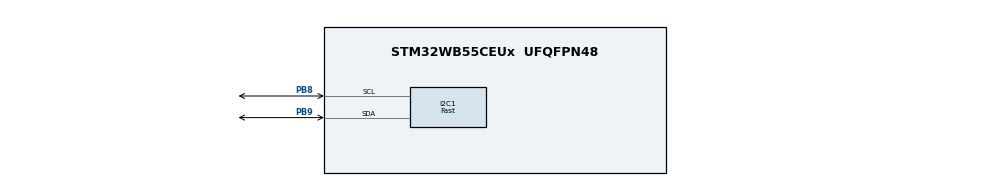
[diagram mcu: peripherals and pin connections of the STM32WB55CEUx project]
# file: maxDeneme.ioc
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I2C1.I2C_Speed_Mode=I2C_Fast
I2C1.Speed=300
I2C1.Timing=0x00000007
Mcu.Family=STM32WB
Mcu.Name=STM32WB55CEUx
Mcu.Package=UFQFPN48
NVIC.PriorityGroup=NVIC_PRIORITYGROUP_4
PB8.Mode=I2C
PB8.Signal=I2C1_SCL
PB9.Mode=I2C
PB9.Signal=I2C1_SDA
ProjectManager.HeapSize=0x200
ProjectManager.StackSize=0x400
ProjectManager.TargetToolchain=STM32CubeIDE
RCC.APB3Freq_Value=16000000
RCC.HSE_VALUE=8000000
RCC.HSI48_VALUE=48000000
RCC.HSI_VALUE=16000000
RCC.LSE_VALUE=32768
RCC.VCOOutputFreq_Value=32000000
board=custom

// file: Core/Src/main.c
/* USER CODE BEGIN Header */
/**
  ******************************************************************************
  * @file           : main.c
  * @brief          : Main program body
  ******************************************************************************
  * @attention
  *
  * Copyright (c) 2023 STMicroelectronics.
  * All rights reserved.
  *
  * This software is licensed under terms that can be found in the LICENSE file
  * in the root directory of this software component.
  * If no LICENSE file comes with this software, it is provided AS-IS.
  *
  ******************************************************************************
  */
/* USER CODE END Header */
#include "main.h"

/* USER CODE BEGIN Includes */
#include "max30102.h"
#include "heartRate.h"
#include "spo2_algorithm.h"
/* USER CODE END Includes */

I2C_HandleTypeDef hi2c1;

void SystemClock_Config(void);
void PeriphCommonClock_Config(void);
static void MX_GPIO_Init(void);
static void MX_I2C1_Init(void);

/* USER CODE BEGIN 0 */
#define MAX_BRIGHTNESS 255

uint32_t irBuffer[100]; //infrared LED sensor data
uint32_t redBuffer[100];  //red LED sensor data

int32_t bufferLength; //data length
int32_t spo2; //SPO2 value
int8_t validSPO2; //indicator to show if the SPO2 calculation is valid
int32_t heartRate; //heart rate value
int8_t validHeartRate; //indicator to show if the heart rate calculation is valid

const uint8_t RATE_SIZE = 4; //Increase this for more averaging. 4 is good.
uint8_t rates[4]; //Array of heart rates
uint8_t rateSpot = 0;
uint32_t lastBeat = 0; //Time at which the last beat occurred

float beatsPerMinute;
int beatAvg;
uint32_t prevTime;
uint8_t flag=0;
uint32_t currentTime;
/* USER CODE END 0 */

int main(void)
{

  /* MCU Configuration--------------------------------------------------------*/

  /* Reset of all peripherals, Initializes the Flash interface and the Systick. */
  HAL_Init();

  /* Configure the system clock */
  SystemClock_Config();

/* Configure the peripherals common clocks */
  PeriphCommonClock_Config();

  /* Initialize all configured peripherals */
  MX_GPIO_Init();
  MX_I2C1_Init();
  /* USER CODE BEGIN 2 */
  SysTick_Config(SystemCoreClock/1000);
  I2C1_init(&hi2c1);
  MAX30102_init();
  //setup(60, 4, 2, 100, 411, 4096);
  //MAX30102_setPulseAmplitudeRed(0x0A);
  /* USER CODE END 2 */

  /* Infinite loop */
  while (1)
  {

    /* USER CODE BEGIN 3 */
	  /*while(1){
		  uint32_t irValue = MAX30102_getIR();

		  if(checkForBeat(irValue) == 1)
		  {
			  //We sensed a beat!
			  long delta = HAL_GetTick() - lastBeat;
			  lastBeat = HAL_GetTick();

			  beatsPerMinute = 60 / (delta / 1000.0);

			  if (beatsPerMinute < 255 && beatsPerMinute > 20)
			  {
				  rates[rateSpot++] = (uint8_t)beatsPerMinute; //Store this reading in the array
				  rateSpot %= RATE_SIZE; //Wrap variable
				  //Take average of readings
				  beatAvg = 0;
				  for (uint8_t x = 0 ; x < RATE_SIZE ; x++)
					  beatAvg += rates[x];
				  beatAvg /= RATE_SIZE;
			  }
		  }
	  }*/
	  bufferLength = 100; //buffer length of 100 stores 4 seconds of samples running at 25sps

	  //read the first 100 samples, and determine the signal range
	  for (uint8_t i = 0 ; i < bufferLength ; i++)
	  {
		  while (MAX30102_available() == 0) //do we have new data?
	      MAX30102_check(); //Check the sensor for new data
	      redBuffer[i] = MAX30102_getRed();
	      irBuffer[i] = MAX30102_getIR();
	      MAX30102_nextSample(); //We're finished with this sample so move to next sample
	  }
	  //calculate heart rate and SpO2 after first 100 samples (first 4 seconds of samples)
	  maxim_heart_rate_and_oxygen_saturation(irBuffer, bufferLength, redBuffer, &spo2, &validSPO2, &heartRate, &validHeartRate);
	  //Continuously taking samples from MAX30102.  Heart rate and SpO2 are calculated every 1 second

	  while (1)
	  {
		  //dumping the first 25 sets of samples in the memory and shift the last 75 sets of samples to the top
		  for (uint8_t i = 25; i < 100; i++)
		  {
			  redBuffer[i - 25] = redBuffer[i];
			  irBuffer[i - 25] = irBuffer[i];
		  }

		  //take 25 sets of samples before calculating the heart rate.
		  for (uint8_t i = 75; i < 100; i++)
		  {
			  while (MAX30102_available() == 0) //do we have new data?
				  MAX30102_check(); //Check the sensor for new data

			  redBuffer[i] = MAX30102_getRed();
			  irBuffer[i] = MAX30102_getIR();

			  MAX30102_nextSample(); //We're finished with this sample so move to next sample
			  uint32_t irValue = irBuffer[i];

			  if(checkForBeat(irValue) == 1)
			  {
				  //We sensed a beat!
				  long delta = HAL_GetTick() - lastBeat;
				  lastBeat = HAL_GetTick();

				  beatsPerMinute = 60 / (delta / 1000.0);

				  if (beatsPerMinute < 255 && beatsPerMinute > 20)
				  {
					  rates[rateSpot++] = (uint8_t)beatsPerMinute; //Store this reading in the array
					  rateSpot %= RATE_SIZE; //Wrap variable
					  //Take average of readings
					  beatAvg = 0;
					  for(uint8_t x = 0; x < 4; x++){
						  beatAvg += rates[x];
					  }
					  beatAvg /= 4;
				  }
			  }

		  }
		  //After gathering 25 new samples recalculate HR and SP02
		  maxim_heart_rate_and_oxygen_saturation(irBuffer, bufferLength, redBuffer, &spo2, &validSPO2, &heartRate, &validHeartRate);
	  }//*/
  }
  /* USER CODE END 3 */
}

void SystemClock_Config(void)
{
  RCC_OscInitTypeDef RCC_OscInitStruct = {0};
  RCC_ClkInitTypeDef RCC_ClkInitStruct = {0};

  /** Configure the main internal regulator output voltage
  */
  __HAL_PWR_VOLTAGESCALING_CONFIG(PWR_REGULATOR_VOLTAGE_SCALE1);

  /** Initializes the RCC Oscillators according to the specified parameters
  * in the RCC_OscInitTypeDef structure.
  */
  RCC_OscInitStruct.OscillatorType = RCC_OSCILLATORTYPE_HSI|RCC_OSCILLATORTYPE_MSI;
  RCC_OscInitStruct.HSIState = RCC_HSI_ON;
  RCC_OscInitStruct.MSIState = RCC_MSI_ON;
  RCC_OscInitStruct.HSICalibrationValue = RCC_HSICALIBRATION_DEFAULT;
  RCC_OscInitStruct.MSICalibrationValue = RCC_MSICALIBRATION_DEFAULT;
  RCC_OscInitStruct.MSIClockRange = RCC_MSIRANGE_6;
  RCC_OscInitStruct.PLL.PLLState = RCC_PLL_NONE;
  if (HAL_RCC_OscConfig(&RCC_OscInitStruct) != HAL_OK)
  {
    Error_Handler();
  }

  /** Configure the SYSCLKSource, HCLK, PCLK1 and PCLK2 clocks dividers
  */
  RCC_ClkInitStruct.ClockType = RCC_CLOCKTYPE_HCLK4|RCC_CLOCKTYPE_HCLK2
                              |RCC_CLOCKTYPE_HCLK|RCC_CLOCKTYPE_SYSCLK
                              |RCC_CLOCKTYPE_PCLK1|RCC_CLOCKTYPE_PCLK2;
  RCC_ClkInitStruct.SYSCLKSource = RCC_SYSCLKSOURCE_MSI;
  RCC_ClkInitStruct.AHBCLKDivider = RCC_SYSCLK_DIV1;
  RCC_ClkInitStruct.APB1CLKDivider = RCC_HCLK_DIV1;
  RCC_ClkInitStruct.APB2CLKDivider = RCC_HCLK_DIV1;
  RCC_ClkInitStruct.AHBCLK2Divider = RCC_SYSCLK_DIV1;
  RCC_ClkInitStruct.AHBCLK4Divider = RCC_SYSCLK_DIV1;

  if (HAL_RCC_ClockConfig(&RCC_ClkInitStruct, FLASH_LATENCY_0) != HAL_OK)
  {
    Error_Handler();
  }
}

void PeriphCommonClock_Config(void)
{
  RCC_PeriphCLKInitTypeDef PeriphClkInitStruct = {0};

  /** Initializes the peripherals clock
  */
  PeriphClkInitStruct.PeriphClockSelection = RCC_PERIPHCLK_SMPS;
  PeriphClkInitStruct.SmpsClockSelection = RCC_SMPSCLKSOURCE_HSI;
  PeriphClkInitStruct.SmpsDivSelection = RCC_SMPSCLKDIV_RANGE1;

  if (HAL_RCCEx_PeriphCLKConfig(&PeriphClkInitStruct) != HAL_OK)
  {
    Error_Handler();
  }
}

static void MX_I2C1_Init(void)
{

  hi2c1.Instance = I2C1;
  hi2c1.Init.Timing = 0x00000007;
  hi2c1.Init.OwnAddress1 = 0;
  hi2c1.Init.AddressingMode = I2C_ADDRESSINGMODE_7BIT;
  hi2c1.Init.DualAddressMode = I2C_DUALADDRESS_DISABLE;
  hi2c1.Init.OwnAddress2 = 0;
  hi2c1.Init.OwnAddress2Masks = I2C_OA2_NOMASK;
  hi2c1.Init.GeneralCallMode = I2C_GENERALCALL_DISABLE;
  hi2c1.Init.NoStretchMode = I2C_NOSTRETCH_DISABLE;
  if (HAL_I2C_Init(&hi2c1) != HAL_OK)
  {
    Error_Handler();
  }

  /** Configure Analogue filter
  */
  if (HAL_I2CEx_ConfigAnalogFilter(&hi2c1, I2C_ANALOGFILTER_ENABLE) != HAL_OK)
  {
    Error_Handler();
  }

  /** Configure Digital filter
  */
  if (HAL_I2CEx_ConfigDigitalFilter(&hi2c1, 0) != HAL_OK)
  {
    Error_Handler();
  }

}

static void MX_GPIO_Init(void)
{

  /* GPIO Ports Clock Enable */
  __HAL_RCC_GPIOB_CLK_ENABLE();

}

void Error_Handler(void)
{
  __disable_irq();
  while (1)
  {
  }
}
